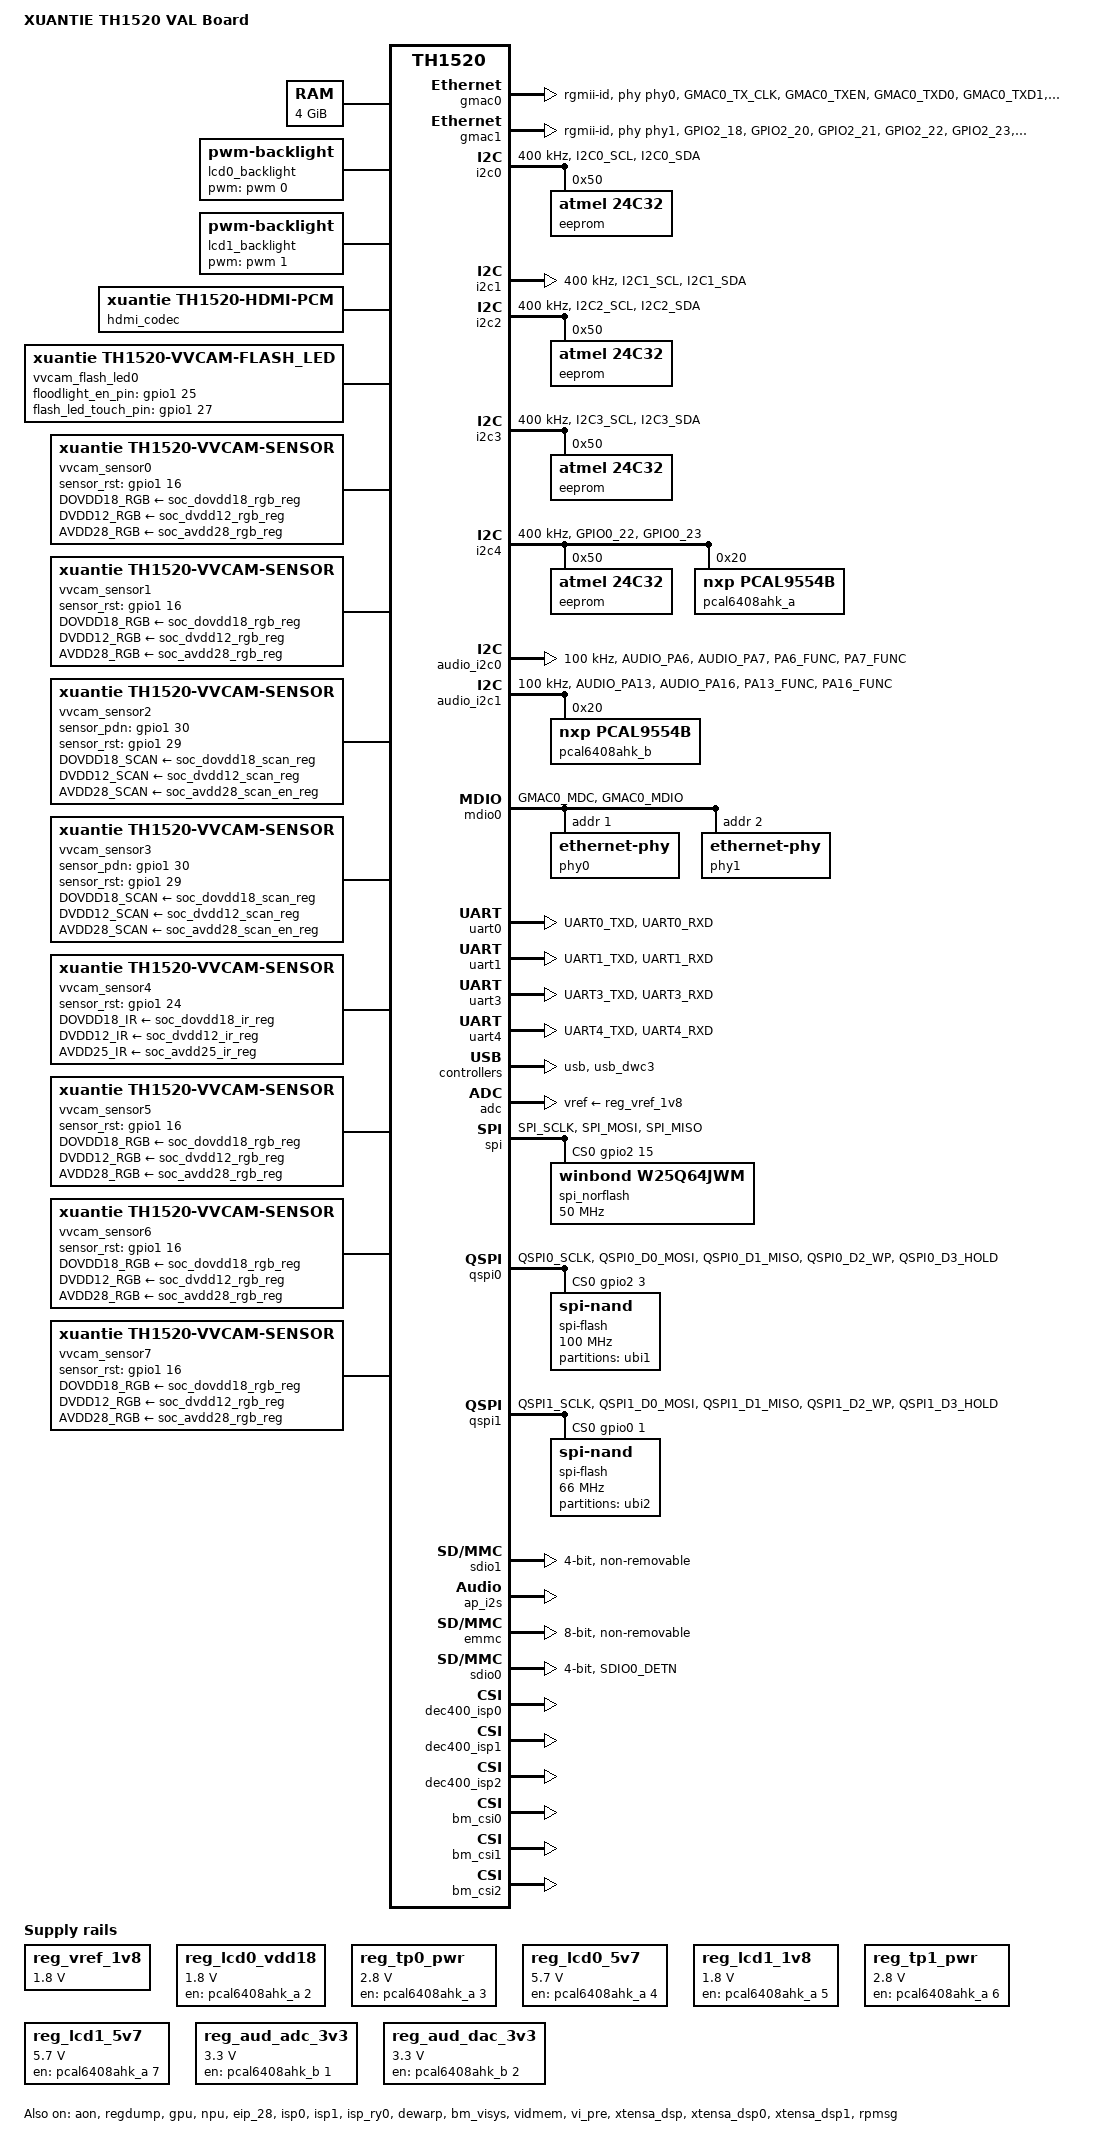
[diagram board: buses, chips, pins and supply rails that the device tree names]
/* SPDX-License-Identifier: GPL-2.0 */
/*
 * Copyright (C) 2021-2024 Alibaba Group Holding Limited.
 */

/dts-v1/;

#include "th1520.dtsi"
#include <dt-bindings/gpio/gpio.h>
#include "th1520-a-val-audio.dtsi"

/ {
	model = "XUANTIE TH1520 VAL Board";
	compatible = "xuantie,th1520-val", "xuantie,th1520", "thead,th1520";

	memory@0 {
		device_type = "memory";
		reg = <0x0 0x200000 0x0 0xffe00000>;
	};

	aliases {
		flash_led0 = &vvcam_flash_led0;
		vivcam0 = &vvcam_sensor0;
		vivcam1 = &vvcam_sensor1;
		vivcam2 = &vvcam_sensor2;
		vivcam3 = &vvcam_sensor3;
		vivcam4 = &vvcam_sensor4;
		vivcam5 = &vvcam_sensor5;
		vivcam6 = &vvcam_sensor6;
		vivcam7 = &vvcam_sensor7;
		viv_video0 =  &video0;
		viv_video1 =  &video1;
		viv_video2 =  &video2;
		viv_video3 =  &video3;
		viv_video4 =  &video4;
		viv_video5 =  &video5;
		viv_video6 =  &video6;
		viv_video7 =  &video7;
		viv_video8 =  &video8;
		viv_video9 =  &video9;
		viv_video10 =  &video10;
		viv_video11 =  &video11;
		viv_video12 =  &video12;
		viv_video15 =  &video15;

	};

	chosen {
		stdout-path = "serial0:115200n8";
	};

	lcd0_backlight: pwm-backlight@0 {
		compatible = "pwm-backlight";
		pwms = <&pwm 0 5000000 0>;
		pinctrl-names = "default";
		pinctrl-0 = <&pwm0_pins>;
		brightness-levels = <0 4 8 16 32 64 128 255>;
		default-brightness-level = <7>;
	};

	lcd1_backlight: pwm-backlight@1 {
		compatible = "pwm-backlight";
		pwms = <&pwm 1 5000000 0>;
		pinctrl-names = "default";
		pinctrl-0 = <&pwm1_pins>;
		brightness-levels = <0 4 8 16 32 64 128 255>;
		default-brightness-level = <7>;
	};

	th1520_iopmp: iopmp {
		compatible = "xuantie,th1520-iopmp";

		/* config#1: multiple valid regions */
		iopmp_emmc: IOPMP_EMMC {
			attr = <0xFFFFFFFF>;
			is_default_region;
		};

		/* config#2: iopmp bypass */
		iopmp_sdio0: IOPMP_SDIO0 {
			bypass_en;
		};

		/* config#3: iopmp default region set */
		iopmp_sdio1: IOPMP_SDIO1 {
			attr = <0xFFFFFFFF>;
			is_default_region;
		};

		iopmp_usb0: IOPMP_USB0 {
			attr = <0xFFFFFFFF>;
			is_default_region;
		};

		iopmp_ao: IOPMP_AO {
			is_default_region;
		};

		iopmp_aud: IOPMP_AUD {
			is_default_region;
		};

		iopmp_chip_dbg: IOPMP_CHIP_DBG {
			is_default_region;
		};

		iopmp_eip120i: IOPMP_EIP120I {
			is_default_region;
		};

		iopmp_eip120ii: IOPMP_EIP120II {
			is_default_region;
		};

		iopmp_eip120iii: IOPMP_EIP120III {
			is_default_region;
		};

		iopmp_isp0: IOPMP_ISP0 {
			is_default_region;
		};

		iopmp_isp1: IOPMP_ISP1 {
			is_default_region;
		};

		iopmp_dw200: IOPMP_DW200 {
			is_default_region;
		};

		iopmp_vipre: IOPMP_VIPRE {
			is_default_region;
		};

		iopmp_venc: IOPMP_VENC {
			is_default_region;
		};

		iopmp_vdec: IOPMP_VDEC {
			is_default_region;
		};

		iopmp_g2d: IOPMP_G2D {
			is_default_region;
		};

		iopmp_fce: IOPMP_FCE {
			is_default_region;
		};

		iopmp_npu: IOPMP_NPU {
			is_default_region;
		};

		iopmp0_dpu: IOPMP0_DPU {
			bypass_en;
		};

		iopmp1_dpu: IOPMP1_DPU {
			bypass_en;
		};

		iopmp_gpu: IOPMP_GPU {
			is_default_region;
		};

		iopmp_gmac1: IOPMP_GMAC1 {
			is_default_region;
		};

		iopmp_gmac2: IOPMP_GMAC2 {
			is_default_region;
		};

		iopmp_dmac: IOPMP_DMAC {
			is_default_region;
		};

		iopmp_tee_dmac: IOPMP_TEE_DMAC {
			is_default_region;
		};

		iopmp_dsp0: IOPMP_DSP0 {
			is_default_region;
		};

		iopmp_dsp1: IOPMP_DSP1 {
			is_default_region;
		};

		iopmp_audio0: IOPMP_AUDIO0 {
			is_default_region;
		};

		iopmp_audio1: IOPMP_AUDIO1 {
			is_default_region;
		};
	};

	reg_vref_1v8: regulator-adc-verf {
		compatible = "regulator-fixed";
		regulator-name = "vref-1v8";
		regulator-min-microvolt = <1800000>;
		regulator-max-microvolt = <1800000>;
		status = "okay";
	};

	reg_lcd0_vdd18: regulator-lcd0-vdd18 {
		compatible = "regulator-fixed";
		regulator-name = "lcd0_en";
		regulator-min-microvolt = <1800000>;
		regulator-max-microvolt = <1800000>;
		gpio = <&pcal6408ahk_a 2 GPIO_ACTIVE_HIGH>;
		enable-active-high;
	};

	reg_tp0_pwr: regulator-tp0-pwr {
		compatible = "regulator-fixed";
		regulator-name = "tp0_pwr";
		regulator-min-microvolt = <2800000>;
		regulator-max-microvolt = <2800000>;
		gpio = <&pcal6408ahk_a 3 GPIO_ACTIVE_HIGH>;
		enable-active-high;
		regulator-always-on;
	};

	reg_lcd0_5v7: regulator-lcd0-vspn57 {
		compatible = "regulator-fixed";
		regulator-name = "lcd0_bias_en";
		regulator-min-microvolt = <5700000>;
		regulator-max-microvolt = <5700000>;
		gpio = <&pcal6408ahk_a 4 GPIO_ACTIVE_HIGH>;
		enable-active-high;
	};

	reg_lcd1_1v8: regulator-lcd1-vdd18 {
		compatible = "regulator-fixed";
		regulator-name = "lcd1_en";
		regulator-min-microvolt = <1800000>;
		regulator-max-microvolt = <1800000>;
		gpio = <&pcal6408ahk_a 5 GPIO_ACTIVE_HIGH>;
		enable-active-high;
	};

	reg_tp1_pwr: regulator-tp1-pwr {
		compatible = "regulator-fixed";
		regulator-name = "tp1_pwr";
		regulator-min-microvolt = <2800000>;
		regulator-max-microvolt = <2800000>;
		gpio = <&pcal6408ahk_a 6 GPIO_ACTIVE_HIGH>;
		enable-active-high;
		regulator-always-on;
	};

	reg_lcd1_5v7: regulator-lcd1-vspn57 {
		compatible = "regulator-fixed";
		regulator-name = "lcd1_bias_en";
		regulator-min-microvolt = <5700000>;
		regulator-max-microvolt = <5700000>;
		gpio = <&pcal6408ahk_a 7 GPIO_ACTIVE_HIGH>;
		enable-active-high;
	};

	reg_aud_adc_3v3: regulator-aud-adc-3v3 {
		compatible = "regulator-fixed";
		regulator-name = "aud_adc_3v3_en";
		regulator-min-microvolt = <3300000>;
		regulator-max-microvolt = <3300000>;
		gpio = <&pcal6408ahk_b 1 GPIO_ACTIVE_HIGH>;
		enable-active-high;
	};

	reg_aud_dac_3v3: regulator-aud-dac-3v3 {
		compatible = "regulator-fixed";
		regulator-name = "aud_dac_3v3_en";
		regulator-min-microvolt = <3300000>;
		regulator-max-microvolt = <3300000>;
		gpio = <&pcal6408ahk_b 2 GPIO_ACTIVE_HIGH>;
		enable-active-high;
	};

	mbox_910t_client2: mbox_910t_client2 {
		compatible = "xuantie,th1520-mbox-client";
		mbox-names = "906";
		mboxes = <&mbox_910t 2 0>;
		audio-mbox-regmap = <&audio_mbox>;
		status = "okay";
	};

	th1520_rpmsg: th1520_rpmsg {
		compatible = "th1520,rpmsg-bus", "simple-bus";
		memory-region = <&rpmsgmem>;
		#address-cells = <2>;
		#size-cells = <2>;
		ranges;
		rpmsg: rpmsg{
			vdev-nums = <1>;
            reg = <0x0 0x1E000000 0 0x10000>;
			compatible = "th1520,th1520-rpmsg";
			log-memory-region = <&audio_log_mem>;
			audio-text-memory-region = <&audio_text_mem>;
			status = "okay";
		};
	};

	hdmi_codec: hdmi_codec@1 {
		#sound-dai-cells = <0>;
		compatible = "xuantie,th1520-hdmi-pcm";
		status = "okay";
		sound-name-prefix = "DUMMY";
	};

	wcn_wifi: wireless-wlan {
		compatible = "wlan-platdata";
		clock-names = "clk_wifi";
		ref-clock-frequency = <24000000>;
		keep_wifi_power_on;
		pinctrl-names = "default";
		pinctrl-0 = <&pinctrl_wifi_wake>;
		wifi_chip_type = "rtl8723ds";
		// WIFI,poweren-gpios = <&ioexp2 4 0>;	to be FIXED !!!
		support_power_ctrl;
		status = "disabled";
	};

	wcn_bt: wireless-bluetooth {
		compatible = "bluetooth-platdata";
		pinctrl-names = "default";
		pinctrl-0 = <&pinctrl_bt_wake>;
		// BT,power-gpios    = <&ioexp2 5 0>;	to be FIXED !!!
		status = "disabled";
	};

	thermal-zones {
		cpu-thermal {
			polling-delay = <1000>;
			polling-delay-passive = <1000>;
			thermal-sensors = <&pvt 0>;

			trips {
				trip_active0: active-0 {
					temperature = <39000>;
					hysteresis = <5000>;
					type = "active";
				};

				trip_active1: active-1 {
					temperature = <50000>;
					hysteresis = <5000>;
					type = "active";
				};

				trip_active2: active-2 {
					temperature = <60000>;
					hysteresis = <5000>;
					type = "active";
				};
			};
		};
	};

	soc {
		compatible = "simple-bus";
		interrupt-parent = <&plic>;
		#address-cells = <2>;
		#size-cells = <2>;
		dma-noncoherent;
		ranges;


		vvcam_flash_led0: vvcam_flash_led@0{
			flash_led_name = "aw36413_aw36515";
			compatible = "xuantie,th1520-vvcam-flash_led";
			floodlight_i2c_bus = /bits/ 8 <2>;
			floodlight_en_pin = <&gpio1 25 GPIO_ACTIVE_HIGH>;
			//projection_i2c_bus = /bits/ 8 <2>;
			flash_led_touch_pin = <&gpio1 27 GPIO_ACTIVE_HIGH>; //flash led touch pin
			status = "okay";
		};

		vvcam_sensor0: vvcam_sensor@0{
			sensor_name = "SC2310";
			compatible = "xuantie,th1520-vvcam-sensor";
			sensor_regulators = "DOVDD18_RGB", "DVDD12_RGB", "AVDD28_RGB";
			sensor_regulator_voltage_uV = <1800000 1200000 2800000>;
			sensor_regulator_timing_us = <70 50 20>;
			sensor_rst = <&gpio1 16 GPIO_ACTIVE_HIGH>;
			sensor_pdn_delay_us = <4000>; //powerdown pin / shutdown pin actived till I2C ready
			DOVDD18_RGB-supply = <&soc_dovdd18_rgb_reg>;
			DVDD12_RGB-supply = <&soc_dvdd12_rgb_reg>;
			AVDD28_RGB-supply = <&soc_avdd28_rgb_reg>;
			i2c_reg_width = /bits/ 8 <2>;
			i2c_data_width = /bits/ 8 <1>;
			i2c_addr = /bits/ 8 <0x30>;
			i2c_bus = /bits/ 8 <3>;
			status = "okay";
		};

		vvcam_sensor1: vvcam_sensor@1 {
			sensor_name = "OV5693";
			compatible = "xuantie,th1520-vvcam-sensor";
			sensor_regulators = "DOVDD18_RGB", "DVDD12_RGB", "AVDD28_RGB";
			sensor_regulator_voltage_uV = <1800000 1200000 2800000>;
			sensor_regulator_timing_us = <70 50 20>;
			sensor_rst = <&gpio1 16 GPIO_ACTIVE_HIGH>;
			sensor_pdn_delay_us = <4000>; //powerdown pin / shutdown pin actived till I2C ready
			DOVDD18_RGB-supply = <&soc_dovdd18_rgb_reg>;
			DVDD12_RGB-supply = <&soc_dvdd12_rgb_reg>;
			AVDD28_RGB-supply = <&soc_avdd28_rgb_reg>;
			i2c_reg_width = /bits/ 8 <2>;
			i2c_data_width = /bits/ 8 <1>;
			i2c_addr = /bits/ 8 <0x36>;
			i2c_bus = /bits/ 8 <3>;
			status = "okay";
		};

		vvcam_sensor2: vvcam_sensor@2 {
			sensor_name = "GC5035";
			compatible = "xuantie,th1520-vvcam-sensor";
			sensor_regulators = "DOVDD18_SCAN", "DVDD12_SCAN", "AVDD28_SCAN";
			sensor_regulator_timing_us = <100 50 0>;
			sensor_pdn = <&gpio1 30 GPIO_ACTIVE_HIGH>; //powerdown pin / shutdown pin
			sensor_rst = <&gpio1 29 GPIO_ACTIVE_HIGH>;
			sensor_pdn_delay_us = <60>; //powerdown pin / shutdown pin actived till I2C ready
			DOVDD18_SCAN-supply = <&soc_dovdd18_scan_reg>;
			DVDD12_SCAN-supply = <&soc_dvdd12_scan_reg>;
			AVDD28_SCAN-supply = <&soc_avdd28_scan_en_reg>;
			i2c_addr = /bits/ 8 <0x37>;
			i2c_bus = /bits/ 8 <4>;
			i2c_reg_width = /bits/ 8 <1>;
			i2c_data_width = /bits/ 8 <1>;
			status = "okay";
		};

		vvcam_sensor3: vvcam_sensor@3 {
			sensor_name = "SC2310";
			compatible = "xuantie,th1520-vvcam-sensor";
			sensor_regulators = "DOVDD18_SCAN", "DVDD12_SCAN", "AVDD28_SCAN";
			sensor_regulator_timing_us = <70 50 20>;
			sensor_pdn = <&gpio1 30 GPIO_ACTIVE_HIGH>; //powerdown pin / shutdown pin
			sensor_rst = <&gpio1 29 GPIO_ACTIVE_HIGH>;
			sensor_pdn_delay_us = <4000>; //powerdown pin / shutdown pin actived till I2C ready
			DOVDD18_SCAN-supply = <&soc_dovdd18_scan_reg>;
			DVDD12_SCAN-supply = <&soc_dvdd12_scan_reg>;
			AVDD28_SCAN-supply = <&soc_avdd28_scan_en_reg>;
			i2c_bus = /bits/ 8 <4>;
			i2c_reg_width = /bits/ 8 <2>;
			i2c_data_width = /bits/ 8 <1>;
			i2c_addr = /bits/ 8 <0x30>;
			status = "okay";
		};

		vvcam_sensor4: vvcam_sensor@4 {
			sensor_name = "SC132GS";
			compatible = "xuantie,th1520-vvcam-sensor";
			sensor_regulators = "DOVDD18_IR", "DVDD12_IR", "AVDD25_IR";
			sensor_regulator_timing_us = <70 1000 2000>;
			i2c_addr = /bits/ 8 <0x31>;
			sensor_rst = <&gpio1 24 GPIO_ACTIVE_HIGH>;
			sensor_pdn_delay_us = <2000>; //powerdown pin / shutdown pin actived till I2C ready
			DOVDD18_IR-supply = <&soc_dovdd18_ir_reg>;
			DVDD12_IR-supply = <&soc_dvdd12_ir_reg>;
			AVDD25_IR-supply = <&soc_avdd25_ir_reg>;
			i2c_reg_width = /bits/ 8 <2>;
			i2c_data_width = /bits/ 8 <1>;
			i2c_bus = /bits/ 8 <2>;
			status = "okay";
		};

		vvcam_sensor5: vvcam_sensor@5 {
			sensor_name = "OV12870";
			compatible = "xuantie,th1520-vvcam-sensor";
			sensor_regulators = "DOVDD18_RGB", "DVDD12_RGB", "AVDD28_RGB";
			sensor_regulator_voltage_uV = <1800000 1200000 2800000>;
			sensor_regulator_timing_us = <100 50 0>;
			sensor_rst = <&gpio1 16 GPIO_ACTIVE_HIGH>;
			sensor_pdn_delay_us = <60>; //powerdown pin / shutdown pin actived till I2C ready
			DOVDD18_RGB-supply = <&soc_dovdd18_rgb_reg>;
			DVDD12_RGB-supply = <&soc_dvdd12_rgb_reg>;
			AVDD28_RGB-supply = <&soc_avdd28_rgb_reg>;
			i2c_addr = /bits/ 8 <0x10>;
			i2c_reg_width = /bits/ 8 <2>;
			i2c_data_width = /bits/ 8 <1>;
			i2c_bus = /bits/ 8 <3>;
			status = "okay";
		};

		vvcam_sensor6: vvcam_sensor@6 {
			sensor_name = "GC02M1B";
			compatible = "xuantie,th1520-vvcam-sensor";
			sensor_regulators = "DOVDD18_RGB", "DVDD12_RGB", "AVDD28_RGB";
			sensor_regulator_voltage_uV = <1800000 1675000 2800000>;
			sensor_regulator_timing_us = <70 50 20>;
			sensor_rst = <&gpio1 16 GPIO_ACTIVE_HIGH>;
			sensor_pdn_delay_us = <1000>; //powerdown pin / shutdown pin actived till I2C ready
			DOVDD18_RGB-supply = <&soc_dovdd18_rgb_reg>;
			DVDD12_RGB-supply = <&soc_dvdd12_rgb_reg>;
			AVDD28_RGB-supply = <&soc_avdd28_rgb_reg>;
			i2c_reg_width = /bits/ 8 <1>;
			i2c_data_width = /bits/ 8 <1>;
			i2c_addr = /bits/ 8 <0x37>;
			i2c_bus = /bits/ 8 <3>;
			status = "okay";
		};

		vvcam_sensor7: vvcam_sensor@7 {
			sensor_name = "IMX334";
			compatible = "xuantie,th1520-vvcam-sensor";
			sensor_regulators = "DOVDD18_RGB", "DVDD12_RGB", "AVDD28_RGB";
			sensor_regulator_timing_us = <70 50 20>;
			sensor_rst = <&gpio1 16 GPIO_ACTIVE_HIGH>;
			sensor_pdn_delay_us = <1000>; //powerdown pin / shutdown pin actived till I2C ready
			DOVDD18_RGB-supply = <&soc_dovdd18_rgb_reg>;
			DVDD12_RGB-supply = <&soc_dvdd12_rgb_reg>;
			AVDD28_RGB-supply = <&soc_avdd28_rgb_reg>;
			i2c_reg_width = /bits/ 8 <2>;
			i2c_data_width = /bits/ 8 <1>;
			i2c_addr = /bits/ 8 <0x1a>;
			i2c_bus = /bits/ 8 <3>;
			status = "okay";
		};

		video0: cam_dev@000 {
			compatible = "xuantie,th1520-video";
			status = "okay";
			vi_mem_pool_region = <2>;	// vi_mem: framebuffer, region[2]
			channel0 {
				sensor0 {
					subdev_name = "vivcam";
					idx = <2>; //<2>=vivcam2 : gc5035
					csi_idx = <1>; //<1>=CSI2X2_B
					mode_idx = <3>;
					path_type = "SENSOR_1296x972_RAW10_LINER"; //SENSOR_VGA_RAW10_LINER//
				};
				sensor1 {
					subdev_name = "vivcam";
					idx = <3>; //<3>=vivcam3 : sc2310
					csi_idx = <1>; //<1>=CSI2X2_B
					mode_idx = <1>;
					path_type = "SENSOR_1920X1088_26FPS_RAW12_LINER";
				};
				dma {
					subdev_name = "vipre";
					idx = <0>;
					path_type = "VIPRE_CSI1_ISP0";
				};
				isp {
					subdev_name = "isp";
					idx = <0>;
					path_type = "ISP_MI_PATH_MP";
					output {
						max_width = <1920>;
						max_height = <1088>;
						bit_per_pixel = <12>;
						frame_count = <3>;
					};
				};
			};
			channel1 {
				sensor0 {
					subdev_name = "vivcam";
					idx = <2>; //<2>=vivcam2 : gc5035
					csi_idx = <1>; //<1>=CSI2X2_B
					mode_idx = <3>;
					path_type = "SENSOR_1296x972_RAW10_LINER"; //SENSOR_VGA_RAW10_LINER//
				};
				sensor1 {
					subdev_name = "vivcam";
					idx = <3>; //<3>=vivcam3 : sc2310
					csi_idx = <1>; //<1>=CSI2X2_B
					mode_idx = <1>;
					path_type = "SENSOR_1920X1088_26FPS_RAW12_LINER";
				};
				dma {
					subdev_name = "vipre";
					idx = <0>;
					path_type = "VIPRE_CSI1_ISP0";
				};
				isp {
					subdev_name = "isp";
					idx = <0>;
					path_type = "ISP_MI_PATH_SP";
					output {
						max_width = <1920>;
						max_height = <1088>;
						bit_per_pixel = <12>;
						frame_count = <3>;
					};
				};
			};
			channel2 {
				sensor0 {
					subdev_name = "vivcam";
					idx = <2>; //<2>=vivcam2 : gc5035
					csi_idx = <1>; //<1>=CSI2X2_B
					mode_idx = <3>;
					path_type = "SENSOR_1296x972_RAW10_LINER"; //SENSOR_VGA_RAW10_LINER//
				};
				sensor1 {
					subdev_name = "vivcam";
					idx = <3>; //<3>=vivcam3 : sc2310
					csi_idx = <1>; //<1>=CSI2X2_B
					mode_idx = <1>;
					path_type = "SENSOR_1920X1088_26FPS_RAW12_LINER";
				};
				dma {
					subdev_name = "vipre";
					idx = <0>;
					path_type = "VIPRE_CSI1_ISP0";
				};
				isp {
					subdev_name = "isp";
					idx = <0>;
					path_type = "ISP_MI_PATH_SP2_BP";
					output {
						max_width = <1920>;
						max_height = <1088>;
						bit_per_pixel = <12>;
						frame_count = <3>;
					};
				};
			};
		};


		video1: cam_dev@100{
			compatible = "xuantie,th1520-video";
			status = "okay";
			vi_mem_pool_region = <2>;	// vi_mem: framebuffer, region[2]
			channel0 {
				sensor0 {
					subdev_name = "vivcam";
					idx = <2>; //<2>=vivcam2 : gc5035
					csi_idx = <1>; //<1>=CSI2X2_B
					mode_idx = <3>;
					path_type = "SENSOR_1296x972_RAW10_LINER";
				};
				sensor1 {
					subdev_name = "vivcam";
					idx = <3>; //<3>=vivcam3 : sc2310
					csi_idx = <1>; //<1>=CSI2X2_B
					mode_idx = <1>;
					path_type = "SENSOR_1920X1088_26FPS_RAW12_LINER";
				};
				dma {
					subdev_name = "vipre";
					idx = <0>;
					path_type = "VIPRE_CSI1_ISP0";
				};
				isp {
					subdev_name = "isp";
					idx = <0>;
					path_type = "ISP_MI_PATH_MP";
					output {
						max_width = <1920>;
						max_height = <1088>;
						bit_per_pixel = <12>;
						frame_count = <3>;
					};
				};
				dw {
					subdev_name = "dw";
					idx = <0>;
					path_type = "DW_DWE_VSE0";
					dw_dst_depth = <2>;
				};
			};
			channel1 {
				sensor0 {
					subdev_name = "vivcam";
					idx = <2>; //<2>=vivcam2 : gc5035
					csi_idx = <1>; //<1>=CSI2X2_B
					mode_idx = <3>;
					path_type = "SENSOR_1296x972_RAW10_LINER";
				};
				sensor1 {
					subdev_name = "vivcam";
					idx = <3>; //<3>=vivcam3 : sc2310
					csi_idx = <1>; //<1>=CSI2X2_B
					mode_idx = <1>;
					path_type = "SENSOR_1920X1088_26FPS_RAW12_LINER";
				};
				dma {
					subdev_name = "vipre";
					idx = <0>;
					path_type = "VIPRE_CSI1_ISP0";
				};
				isp {
					subdev_name = "isp";
					idx = <0>;
					path_type = "ISP_MI_PATH_MP";
					output {
						max_width = <1920>;
						max_height = <1088>;
						bit_per_pixel = <12>;
						frame_count = <3>;
					};
				};
				dw {
					subdev_name = "dw";
					idx = <0>;
					path_type = "DW_DWE_VSE1";
					dw_dst_depth = <2>;
				};
			};
			channel2 {
				sensor0 {
					subdev_name = "vivcam";
					idx = <2>; //<2>=vivcam2 : gc5035
					csi_idx = <1>; //<1>=CSI2X2_B
					mode_idx = <3>;
					path_type = "SENSOR_1296x972_RAW10_LINER";
				};
				sensor1 {
					subdev_name = "vivcam";
					idx = <3>; //<3>=vivcam3 : sc2310
					csi_idx = <1>; //<1>=CSI2X2_B
					mode_idx = <1>;
					path_type = "SENSOR_1920X1088_26FPS_RAW12_LINER";
				};
				dma {
					subdev_name = "vipre";
					idx = <0>;
					path_type = "VIPRE_CSI1_ISP0";
				};
				isp {
					subdev_name = "isp";
					idx = <0>;
					path_type = "ISP_MI_PATH_MP";
					output {
						max_width = <1920>;
						max_height = <1088>;
						bit_per_pixel = <12>;
						frame_count = <3>;
					};
				};
				dw {
					subdev_name = "dw";
					idx = <0>;
					path_type = "DW_DWE_VSE2";
					dw_dst_depth = <2>;
				};
			};
		};

		video2: cam_dev@200{
			compatible = "xuantie,th1520-video";
			status = "okay";
			vi_mem_pool_region = <0>;	// vi_mem: framebuffer, region[0]
			channel0 {
				sensor0 {
					subdev_name = "vivcam";
					idx = <0>; //sc2310
					csi_idx = <0>; //<0>=CSI2
					mode_idx = <1>;
					path_type = "SENSOR_1920X1088_26FPS_RAW12_LINER";
				};
				sensor1 {
					subdev_name = "vivcam";
					idx = <6>; //gc02m1b
					csi_idx = <0>; //<0>=CSI2
					mode_idx = <0>;
					path_type = "SENSOR_1600x1200_RAW10_LINER";
				};
				sensor2 {
					subdev_name = "vivcam";
					idx = <7>; //imx334
					csi_idx = <0>; //<0>=CSI2
					mode_idx = <0>;
					path_type = "SENSOR_3840x2180_RAW12_LINER";
				};
				dma {
					subdev_name = "vipre";
					idx = <0>;
					path_type = "VIPRE_CSI0_ISP1";
				};
				isp {
					subdev_name = "isp";
					idx = <1>;
					path_type = "ISP_MI_PATH_MP";
					output {
						max_width = <3840>;
						max_height = <2180>;
						bit_per_pixel = <16>;
						frame_count = <3>;
					};
				};
			};
			channel1 {
				sensor0 {
					subdev_name = "vivcam";
					idx = <0>; //sc2310
					csi_idx = <0>; //<0>=CSI2
					mode_idx = <1>;
					path_type = "SENSOR_1920X1088_26FPS_RAW12_LINER";
				};
				sensor1 {
					subdev_name = "vivcam";
					idx = <6>; //gc02m1b
					csi_idx = <0>; //<0>=CSI2
					mode_idx = <0>;
					path_type = "SENSOR_1600x1200_RAW10_LINER";
				};
				dma {
					subdev_name = "vipre";
					idx = <0>;
					path_type = "VIPRE_CSI0_ISP1";
				};
				isp {
					subdev_name = "isp";
					idx = <1>;
					path_type = "ISP_MI_PATH_SP";
					output {
						max_width = <1920>;
						max_height = <1088>;
						bit_per_pixel = <16>;
						frame_count = <3>;
					};
				};
			};
			channel2 {
				sensor0 {
					subdev_name = "vivcam";
					idx = <0>; //sc2310
					csi_idx = <0>; //<0>=CSI2
					mode_idx = <1>;
					path_type = "SENSOR_1920X1088_26FPS_RAW12_LINER";
				};
				sensor1 {
					subdev_name = "vivcam";
					idx = <6>; //gc02m1b
					csi_idx = <0>; //<0>=CSI2
					mode_idx = <0>;
					path_type = "SENSOR_1600x1200_RAW10_LINER";
				};
				dma {
					subdev_name = "vipre";
					idx = <0>;
					path_type = "VIPRE_CSI0_ISP1";
				};
				isp {
					subdev_name = "isp";
					idx = <1>;
					path_type = "ISP_MI_PATH_SP2_BP";
					output {
						max_width = <1920>;
						max_height = <1088>;
						bit_per_pixel = <16>;
						frame_count = <3>;
					};
				};
			};
		};

		video3: cam_dev@300{
			compatible = "xuantie,th1520-video";
			status = "okay";
			vi_mem_pool_region = <0>;	// vi_mem: framebuffer, region[0]
			channel0 {
				sensor0 {
					subdev_name = "vivcam";
					idx = <0>; //sc2310
					csi_idx = <0>; //<0>=CSI2
					mode_idx = <1>;
					path_type = "SENSOR_1920X1088_26FPS_RAW12_LINER";
				};
				sensor1 {
					subdev_name = "vivcam";
					idx = <6>; //gc02m1b
					csi_idx = <0>; //<0>=CSI2
					mode_idx = <0>;
					path_type = "SENSOR_1600x1200_RAW10_LINER";
				};
				dma {
					subdev_name = "vipre";
					idx = <0>;
					path_type = "VIPRE_CSI0_ISP1";
				};
				isp {
					subdev_name = "isp";
					idx = <1>;
					path_type = "ISP_MI_PATH_MP";
					output {
						max_width = <1920>;
						max_height = <1088>;
						bit_per_pixel = <12>;
						frame_count = <3>;
					};
				};
				dw {
					subdev_name = "dw";
					idx = <0>;
					path_type = "DW_DWE_VSE0";
					dw_dst_depth = <2>;
				};
			};
			channel1 {
				sensor0 {
					subdev_name = "vivcam";
					idx = <0>; //sc2310
					csi_idx = <0>; //<0>=CSI2
					mode_idx = <1>;
					path_type = "SENSOR_1920X1088_26FPS_RAW12_LINER";
				};
				sensor1 {
					subdev_name = "vivcam";
					idx = <6>; //gc02m1b
					csi_idx = <0>; //<0>=CSI2
					mode_idx = <0>;
					path_type = "SENSOR_1600x1200_RAW10_LINER";
				};
				dma {
					subdev_name = "vipre";
					idx = <0>;
					path_type = "VIPRE_CSI0_ISP1";
				};
				isp {
					subdev_name = "isp";
					idx = <1>;
					path_type = "ISP_MI_PATH_MP";
					output {
						max_width = <1920>;
						max_height = <1088>;
						bit_per_pixel = <12>;
						frame_count = <3>;
					};
				};
				dw {
					subdev_name = "dw";
					idx = <0>;
					path_type = "DW_DWE_VSE1";
					dw_dst_depth = <2>;
				};
			};
			channel2 {
				sensor0 {
					subdev_name = "vivcam";
					idx = <0>; //sc2310
					csi_idx = <0>; //<0>=CSI2
					mode_idx = <1>;
					path_type = "SENSOR_1920X1088_26FPS_RAW12_LINER";
				};
				sensor1 {
					subdev_name = "vivcam";
					idx = <6>; //gc02m1b
					csi_idx = <0>; //<0>=CSI2
					mode_idx = <0>;
					path_type = "SENSOR_1600x1200_RAW10_LINER";
				};
				dma {
					subdev_name = "vipre";
					idx = <0>;
					path_type = "VIPRE_CSI0_ISP1";
				};
				isp {
					subdev_name = "isp";
					idx = <1>;
					path_type = "ISP_MI_PATH_MP";
					output {
						max_width = <1920>;
						max_height = <1088>;
						bit_per_pixel = <12>;
						frame_count = <3>;
					};
				};
				dw {
					subdev_name = "dw";
					idx = <0>;
					path_type = "DW_DWE_VSE2";
					dw_dst_depth = <2>;
				};
			};
		};

		video4: cam_dev@400{
			compatible = "xuantie,th1520-video";
			status = "okay";
			vi_mem_pool_region = <0>;	// vi_mem: framebuffer, region[0]
			channel0 {
				sensor0 {
					subdev_name = "vivcam";
					idx = <0>; //sc2310
					csi_idx = <0>; //<0>=CSI2
					mode_idx = <1>;
					path_type = "SENSOR_1920X1088_26FPS_RAW12_LINER";
				};
				sensor1 {
					subdev_name = "vivcam";
					idx = <6>; //gc02m1b
					csi_idx = <0>; //<0>=CSI2
					mode_idx = <0>;
					path_type = "SENSOR_1600x1200_RAW10_LINER";
				};
				dma {
					subdev_name = "vipre";
					idx = <0>;
					path_type = "VIPRE_CSI0_ISP1";
				};
				isp {
					subdev_name = "isp";
					idx = <1>;
					path_type = "ISP_MI_PATH_PP";
					output {
						max_width = <1920>;
						max_height = <1088>;
						bit_per_pixel = <12>;
						frame_count = <3>;
					};
				};
				dsp {
					subdev_name = "dsp";
					idx = <0>;
					path_type = "DSP_PATH_ISP_RY";
					output {
						max_width = <1920>;
						max_height = <1088>;
						bit_per_pixel = <12>;
						frame_count = <3>;
					};
				};
				ry {
					subdev_name = "ry";
					idx = <0>;
					path_type = "ISP_RY_MI_PATH_MP";
					output {
						max_width = <1920>;
						max_height = <1088>;
						bit_per_pixel = <12>;
						frame_count = <3>;
					};
				};
			};
			channel1 {
				sensor0 {
					subdev_name = "vivcam";
					idx = <0>; //sc2310
					csi_idx = <0>; //<0>=CSI2
					mode_idx = <1>;
					path_type = "SENSOR_1920X1088_26FPS_RAW12_LINER";
				};
				sensor1 {
					subdev_name = "vivcam";
					idx = <6>; //gc02m1b
					csi_idx = <0>; //<0>=CSI2
					mode_idx = <0>;
					path_type = "SENSOR_1600x1200_RAW10_LINER";
				};
				dma {
					subdev_name = "vipre";
					idx = <0>;
					path_type = "VIPRE_CSI0_ISP1";
				};
				isp {
					subdev_name = "isp";
					idx = <1>;
					path_type = "ISP_MI_PATH_PP";
					output {
						max_width = <1920>;
						max_height = <1088>;
						bit_per_pixel = <12>;
						frame_count = <3>;
					};
				};
				dsp {
					subdev_name = "dsp";
					idx = <0>;
					path_type = "DSP_PATH_ISP_RY";
					output {
						max_width = <1920>;
						max_height = <1088>;
						bit_per_pixel = <12>;
						frame_count = <3>;
					};
				};
				ry {
					subdev_name = "ry";
					idx = <0>;
					path_type = "ISP_RY_MI_PATH_SP";
					output {
						max_width = <1920>;
						max_height = <1088>;
						bit_per_pixel = <12>;
						frame_count = <3>;
					};
				};
			};
			channel2 {
				sensor0 {
					subdev_name = "vivcam";
					idx = <0>; //sc2310
					csi_idx = <0>; //<0>=CSI2
					mode_idx = <1>;
					path_type = "SENSOR_1920X1088_26FPS_RAW12_LINER";
				};
				sensor1 {
					subdev_name = "vivcam";
					idx = <6>; //gc02m1b
					csi_idx = <0>; //<0>=CSI2
					mode_idx = <0>;
					path_type = "SENSOR_1600x1200_RAW10_LINER";
				};
				dma {
					subdev_name = "vipre";
					idx = <0>;
					path_type = "VIPRE_CSI0_ISP1";
				};
				isp {
					subdev_name = "isp";
					idx = <1>;
					path_type = "ISP_MI_PATH_PP";
					output {
						max_width = <1920>;
						max_height = <1088>;
						bit_per_pixel = <12>;
						frame_count = <3>;
					};
				};
				dsp {
					subdev_name = "dsp";
					idx = <0>;
					path_type = "DSP_PATH_ISP_RY";
					output {
						max_width = <1920>;
						max_height = <1088>;
						bit_per_pixel = <12>;
						frame_count = <3>;
					};
				};
				ry {
					subdev_name = "ry";
					idx = <0>;
					path_type = "ISP_RY_MI_PATH_SP2_BP";
					output {
						max_width = <1920>;
						max_height = <1088>;
						bit_per_pixel = <12>;
						frame_count = <3>;
					};
				};
			};
		};

		video5: cam_dev@500{
			compatible = "xuantie,th1520-video";
			status = "okay";
			vi_mem_pool_region = <0>;	// vi_mem: framebuffer, region[0]
			channel0 {
				sensor0 {
					subdev_name = "vivcam";
					idx = <0>; //sc2310
					csi_idx = <0>; //<0>=CSI2
					mode_idx = <1>;
					path_type = "SENSOR_1920X1088_26FPS_RAW12_LINER";
				};
				sensor1 {
					subdev_name = "vivcam";
					idx = <6>; //gc02m1b
					csi_idx = <0>; //<0>=CSI2
					mode_idx = <0>;
					path_type = "SENSOR_1600x1200_RAW10_LINER";
				};
				dma {
					subdev_name = "vipre";
					idx = <0>;
					path_type = "VIPRE_CSI0_ISP1";
				};
				isp {
					subdev_name = "isp";
					idx = <1>;
					path_type = "ISP_MI_PATH_PP";
					output {
						max_width = <1920>;
						max_height = <1088>;
						bit_per_pixel = <12>;
						frame_count = <3>;
					};
				};
				dsp {
					subdev_name = "dsp";
					idx = <0>;
					path_type = "DSP_PATH_ISP_RY";
					output {
						max_width = <1920>;
						max_height = <1088>;
						bit_per_pixel = <12>;
						frame_count = <3>;
					};
				};
				ry {
					subdev_name = "ry";
					idx = <0>;
					path_type = "ISP_RY_MI_PATH_MP";
					output {
						max_width = <1920>;
						max_height = <1088>;
						bit_per_pixel = <12>;
						frame_count = <3>;
					};
				};
				dw {
					subdev_name = "dw";
					idx = <0>;
					path_type = "DW_DWE_VSE0";
					dw_dst_depth = <2>;
				};
			};
			channel1 {
				sensor0 {
					subdev_name = "vivcam";
					idx = <0>; //sc2310
					csi_idx = <0>; //<0>=CSI2
					mode_idx = <1>;
					path_type = "SENSOR_1920X1088_26FPS_RAW12_LINER";
				};
				sensor1 {
					subdev_name = "vivcam";
					idx = <6>; //gc02m1b
					csi_idx = <0>; //<0>=CSI2
					mode_idx = <0>;
					path_type = "SENSOR_1600x1200_RAW10_LINER";
				};
				dma {
					subdev_name = "vipre";
					idx = <0>;
					path_type = "VIPRE_CSI0_ISP1";
				};
				isp {
					subdev_name = "isp";
					idx = <1>;
					path_type = "ISP_MI_PATH_PP";
					output {
						max_width = <1920>;
						max_height = <1088>;
						bit_per_pixel = <12>;
						frame_count = <3>;
					};
				};
				dsp {
					subdev_name = "dsp";
					idx = <0>;
					path_type = "DSP_PATH_ISP_RY";
					output {
						max_width = <1920>;
						max_height = <1088>;
						bit_per_pixel = <12>;
						frame_count = <3>;
					};
				};
				ry {
					subdev_name = "ry";
					idx = <0>;
					path_type = "ISP_RY_MI_PATH_MP";
					output {
						max_width = <1920>;
						max_height = <1088>;
						bit_per_pixel = <12>;
						frame_count = <3>;
					};
				};
				dw {
					subdev_name = "dw";
					idx = <0>;
					path_type = "DW_DWE_VSE1";
					dw_dst_depth = <2>;
				};
			};
			channel2 {
				sensor0 {
					subdev_name = "vivcam";
					idx = <0>; //sc2310
					csi_idx = <0>; //<0>=CSI2
					mode_idx = <1>;
					path_type = "SENSOR_1920X1088_26FPS_RAW12_LINER";
				};
				sensor1 {
					subdev_name = "vivcam";
					idx = <6>; //gc02m1b
					csi_idx = <0>; //<0>=CSI2
					mode_idx = <0>;
					path_type = "SENSOR_1600x1200_RAW10_LINER";
				};
				dma {
					subdev_name = "vipre";
					idx = <0>;
					path_type = "VIPRE_CSI0_ISP1";
				};
				isp {
					subdev_name = "isp";
					idx = <1>;
					path_type = "ISP_MI_PATH_PP";
					output {
						max_width = <1920>;
						max_height = <1088>;
						bit_per_pixel = <12>;
						frame_count = <3>;
					};
				};
				dsp {
					subdev_name = "dsp";
					idx = <0>;
					path_type = "DSP_PATH_ISP_RY";
					output {
						max_width = <1920>;
						max_height = <1088>;
						bit_per_pixel = <12>;
						frame_count = <3>;
					};
				};
				ry {
					subdev_name = "ry";
					idx = <0>;
					path_type = "ISP_RY_MI_PATH_MP";
					output {
						max_width = <1920>;
						max_height = <1088>;
						bit_per_pixel = <12>;
						frame_count = <3>;
					};
				};
				dw {
					subdev_name = "dw";
					idx = <0>;
					path_type = "DW_DWE_VSE2";
					dw_dst_depth = <2>;
				};
			};
		};

		video6: cam_dev@600{
			compatible = "xuantie,th1520-video";
			status = "okay";
			vi_mem_pool_region = <1>;	// vi_mem: framebuffer, region[1]
			channel0 {
				sensor0 {
					subdev_name = "vivcam";
					idx = <4>; //sc132gs
					csi_idx = <2>; //<2>=CSI2X2_A
					flash_led_idx = <0>;
					mode_idx = <0>;
					path_type = "SENSOR_1080X1280_30FPS_RAW10_LINER";
				};
				dma {
					subdev_name = "vipre";
					idx = <0>;
					path_type = "VIPRE_CSI2_DSP";
				};
				dsp{
					subdev_name = "dsp";
					idx = <1>;
					path_type = "DSP_PATH_VIPRE_ODD";
					output {
						max_width = <1080>;
						max_height = <1280>;
						bit_per_pixel = <16>;
						frame_count = <3>;
					};
				};
			};
			channel1 {
				sensor0 {
					subdev_name = "vivcam";
					idx = <4>; //sc132gs
					csi_idx = <2>; //<2>=CSI2X2_A
					flash_led_idx = <0>;
					mode_idx = <0>;
					path_type = "SENSOR_1080X1280_30FPS_RAW10_LINER";
				};
				dma {
					subdev_name = "vipre";
					idx = <0>;
					path_type = "VIPRE_CSI2_DSP";
				};
				dsp{
					subdev_name = "dsp";
					idx = <1>;
					path_type = "DSP_PATH_VIPRE_EVEN";
					output {
						max_width = <1080>;
						max_height = <1280>;
						bit_per_pixel = <16>;
						frame_count = <3>;
					};
				};
			};
		};

		video7: cam_dev@700{
			compatible = "xuantie,th1520-video";
			status = "okay";
			channel0 {
				sensor0 {
					subdev_name = "vivcam";
					idx = <2>; //<2>=vivcam2 : gc5035
					csi_idx = <1>; //<1>=CSI2X2_B
					mode_idx = <3>;
					path_type = "SENSOR_1296x972_RAW10_LINER"; //SENSOR_VGA_RAW10_LINER//
				};
				sensor1 {
					subdev_name = "vivcam";
					idx = <3>; //<3>=vivcam3 : sc2310
					csi_idx = <1>; //<1>=CSI2X2_B
					mode_idx = <1>;
					path_type = "SENSOR_1920X1088_26FPS_RAW12_LINER";
				};
				dma {
					subdev_name = "vipre";
					idx = <0>;
					path_type = "VIPRE_CSI1_ISP0";
				};
				isp {
					subdev_name = "isp";
					idx = <0>;
					path_type = "ISP_MI_PATH_PP";
					output {
						max_width = <1920>;
						max_height = <1088>;
						bit_per_pixel = <12>;
						frame_count = <3>;
					};
				};
				dsp {
					subdev_name = "dsp";
					idx = <1>;
					path_type = "DSP_PATH_ISP_RY";
					output {
						max_width = <1920>;
						max_height = <1088>;
						bit_per_pixel = <12>;
						frame_count = <3>;
					};
				};
				ry {
					subdev_name = "ry";
					idx = <0>;
					path_type = "ISP_RY_MI_PATH_MP";
					output {
						max_width = <1920>;
						max_height = <1088>;
						bit_per_pixel = <12>;
						frame_count = <3>;
					};
				};
				dw {
					subdev_name = "dw";
					idx = <0>;
					path_type = "DW_DWE_VSE0";
					dw_dst_depth = <2>;
				};
			};
			channel1 {
				sensor0 {
					subdev_name = "vivcam";
					idx = <2>; //<2>=vivcam2 : gc5035
					csi_idx = <1>; //<1>=CSI2X2_B
					mode_idx = <3>;
					path_type = "SENSOR_1296x972_RAW10_LINER"; //SENSOR_VGA_RAW10_LINER//
				};
				sensor1 {
					subdev_name = "vivcam";
					idx = <3>; //<3>=vivcam3 : sc2310
					csi_idx = <1>; //<1>=CSI2X2_B
					mode_idx = <1>;
					path_type = "SENSOR_1920X1088_26FPS_RAW12_LINER";
				};
				dma {
					subdev_name = "vipre";
					idx = <0>;
					path_type = "VIPRE_CSI1_ISP0";
				};
				isp {
					subdev_name = "isp";
					idx = <0>;
					path_type = "ISP_MI_PATH_PP";
					output {
						max_width = <1920>;
						max_height = <1088>;
						bit_per_pixel = <12>;
						frame_count = <3>;
					};
				};
				dsp {
					subdev_name = "dsp";
					idx = <1>;
					path_type = "DSP_PATH_ISP_RY";
					output {
						max_width = <1920>;
						max_height = <1088>;
						bit_per_pixel = <12>;
						frame_count = <3>;
					};
				};
				ry {
					subdev_name = "ry";
					idx = <0>;
					path_type = "ISP_RY_MI_PATH_MP";
					output {
						max_width = <1920>;
						max_height = <1088>;
						bit_per_pixel = <12>;
						frame_count = <3>;
					};
				};
				dw {
					subdev_name = "dw";
					idx = <0>;
					path_type = "DW_DWE_VSE1";
					dw_dst_depth = <2>;
				};
			};
			channel2 {
				sensor0 {
					subdev_name = "vivcam";
					idx = <2>; //<2>=vivcam2 : gc5035
					csi_idx = <1>; //<1>=CSI2X2_B
					mode_idx = <3>;
					path_type = "SENSOR_1296x972_RAW10_LINER"; //SENSOR_VGA_RAW10_LINER//
				};
				sensor1 {
					subdev_name = "vivcam";
					idx = <3>; //<3>=vivcam3 : sc2310
					csi_idx = <1>; //<1>=CSI2X2_B
					mode_idx = <1>;
					path_type = "SENSOR_1920X1088_26FPS_RAW12_LINER";
				};
				dma {
					subdev_name = "vipre";
					idx = <0>;
					path_type = "VIPRE_CSI1_ISP0";
				};
				isp {
					subdev_name = "isp";
					idx = <0>;
					path_type = "ISP_MI_PATH_PP";
					output {
						max_width = <1920>;
						max_height = <1088>;
						bit_per_pixel = <12>;
						frame_count = <3>;
					};
				};
				dsp {
					subdev_name = "dsp";
					idx = <1>;
					path_type = "DSP_PATH_ISP_RY";
					output {
						max_width = <1920>;
						max_height = <1088>;
						bit_per_pixel = <12>;
						frame_count = <3>;
					};
				};
				ry {
					subdev_name = "ry";
					idx = <0>;
					path_type = "ISP_RY_MI_PATH_MP";
					output {
						max_width = <1920>;
						max_height = <1088>;
						bit_per_pixel = <12>;
						frame_count = <3>;
					};
				};
				dw {
					subdev_name = "dw";
					idx = <0>;
					path_type = "DW_DWE_VSE2";
					dw_dst_depth = <2>;
				};
			};
		};


		video8: cam_dev@800{
			compatible = "xuantie,th1520-video";
			status = "okay";
			vi_mem_pool_region = <1>;	// vi_mem: framebuffer, region[1]
			channel0 {
				sensor0 {
					subdev_name = "vivcam";
					idx = <2>; //<2>=vivcam2 : gc5035
					csi_idx = <1>; //<1>=CSI2X2_B
					mode_idx = <3>;
					path_type = "SENSOR_1296x972_RAW10_LINER"; //SENSOR_VGA_RAW10_LINER//
				};
				sensor1 {
					subdev_name = "vivcam";
					idx = <3>; //<3>=vivcam3 : sc2310
					csi_idx = <1>; //<1>=CSI2X2_B
					mode_idx = <1>;
					path_type = "SENSOR_1920X1088_26FPS_RAW12_LINER";
				};
				dma {
					subdev_name = "vipre";
					idx = <0>;
					path_type = "VIPRE_CSI1_DSP";
				};
				dsp {
					subdev_name = "dsp";
					idx = <0>;
					path_type = "DSP_PATH_VIPRE_DDR";
					output {
						max_width = <1920>;
						max_height = <1088>;
						bit_per_pixel = <12>;
						frame_count = <3>;
					};
				};
			};
		};

		video9: cam_dev@900{
			compatible = "xuantie,th1520-video";
			status = "okay";
			channel0 {
				sensor0 {
					subdev_name = "vivcam";
					idx = <4>; //sc132gs
					csi_idx = <2>; //<2>=CSI2X2_A
					mode_idx = <0>;
					path_type = "SENSOR_1080X1280_30FPS_RAW10_LINER";
				};
				dma {
					subdev_name = "vipre";
					idx = <0>;
					path_type = "VIPRE_CSI2_DSP";
				};
				dsp{
					subdev_name = "dsp";
					idx = <1>;
					path_type = "DSP_PATH_VIPRE_DDR";
					output {
						max_width = <1080>;
						max_height = <1280>;
						bit_per_pixel = <16>;
						frame_count = <3>;
					};
				};
			};
		};


		video10: cam_dev@a00{
			compatible = "xuantie,th1520-video";
			status = "okay";
			channel0 {
				sensor0 {
					subdev_name = "vivcam";
					idx = <2>; //<2>=vivcam2 : gc5035
					csi_idx = <1>; //<1>=CSI2X2_B
					mode_idx = <1>;
					path_type = "SENSOR_1080P_RAW10_LINER"; //SENSOR_VGA_RAW10_LINER//
					skip_init = <1>;
				};
				sensor1 {
					subdev_name = "vivcam";
					idx = <3>; //<3>=vivcam3 : sc2310
					csi_idx = <1>; //<1>=CSI2X2_B
					mode_idx = <1>;
					path_type = "SENSOR_1920X1088_26FPS_RAW12_LINER";
					skip_init = <1>;
				};
			};
			dma {
				subdev_name = "vipre";
				idx = <0>;
				path_type = "VIPRE_CSI1_ISP0";
			};
		};

		video11: cam_dev@b00{
			compatible = "xuantie,th1520-video";
			status = "okay";
			channel0 {
				channel_id = <0>;
				status = "okay";
				sensor0 {
					subdev_name = "vivcam";
					idx = <4>; //sc132gs
					csi_idx = <2>; //<2>=CSI2X2_A
					flash_led_idx = <0>;
					mode_idx = <0>;
					path_type = "SENSOR_1080X1280_30FPS_RAW10_LINER";
				};
				dma {
					subdev_name = "vipre";
					idx = <0>;
					path_type = "VIPRE_CSI2_ISP0";
				};
				isp {
					subdev_name = "isp";
					idx = <0>;
					path_type = "ISP_MI_PATH_MP";
					output {
						max_width = <1920>;
						max_height = <1088>;
						bit_per_pixel = <12>;
						frame_count = <3>;
					};
				};
			};
		};

		video12: cam_dev@c00{ // TUNINGTOOL
			compatible = "xuantie,th1520-video";
			status = "okay";
			channel0 { // CSI2
				sensor0 {
					subdev_name = "vivcam";
					idx = <0>; //sc2310
					csi_idx = <0>; //<0>=CSI2
					mode_idx = <1>;
					path_type = "SENSOR_1920X1088_26FPS_RAW12_LINER";
					skip_init = <1>;
				};
				sensor1 {
					subdev_name = "vivcam";
					idx = <6>; //gc02m1b
					csi_idx = <0>; //<0>=CSI2
					mode_idx = <0>;
					path_type = "SENSOR_1600x1200_RAW10_LINER";
					skip_init = <1>;
				};
			};
			dma {
				subdev_name = "vipre";
				idx = <0>;
				path_type = "VIPRE_CSI0_ISP0";
			};
		};

		video15: cam_dev@f00{
			compatible = "xuantie,th1520-video";
			status = "okay";
			vi_mem_pool_region = <0>;
			channel0 {
				channel_id = <0>;
				status = "okay";
				sensor0 {
					subdev_name = "vivcam";
					idx = <0>; //<0>=vivcam0 :2310
					csi_idx = <0>; //<0>=CSI2
					flash_led_idx = <0>;
					mode_idx = <1>;
					path_type = "SENSOR_1920X1088_26FPS_RAW12_LINER";
				};
				sensor1 {
					subdev_name = "vivcam";
					idx = <7>; //imx334
					csi_idx = <0>; //<0>=CSI2
					mode_idx = <0>;
					path_type = "SENSOR_3840x2180_RAW12_LINER";
				};
				dma {
					subdev_name = "vipre";
					idx = <0>;
					path_type = "VIPRE_CSI0_DDR";
				};
			};
		};
	};
};

&gmac0 {
	pinctrl-names = "default";
	pinctrl-0 = <&gmac0_pins>;
	phy-handle = <&phy0>;
	phy-mode = "rgmii-id";
	status = "okay";
};

&gmac1 {
	pinctrl-names = "default";
	pinctrl-0 = <&gmac1_pins>;
	phy-handle = <&phy1>;
	phy-mode = "rgmii-id";
	status = "okay";
};

&i2c0 {
	pinctrl-names = "default";
	pinctrl-0 = <&i2c0_pins>;
	clock-frequency = <400000>;
	i2c-sda-hold-time-ns = <300>;
	i2c-sda-falling-time-ns = <510>;
	i2c-scl-falling-time-ns = <510>;
	status = "okay";

	eeprom@50 {
		compatible = "atmel,24c32";
		reg = <0x50>;
		pagesize = <32>;
	};

	touch@5d {
			#gpio-cells = <2>;
			reg = <0x5d>;
			interrupts = <8 IRQ_TYPE_LEVEL_LOW>;
			irq-gpios = <&gpio1 8 0>;
			reset-gpios = <&gpio1 7 0>;
			AVDD28-supply = <&reg_tp0_pwr>;
			status = "disbale";
	};
};

&i2c1 {
	pinctrl-names = "default";
	pinctrl-0 = <&i2c1_pins>;
	clock-frequency = <400000>;
	i2c-sda-hold-time-ns = <300>;
	i2c-sda-falling-time-ns = <510>;
	i2c-scl-falling-time-ns = <510>;
	status = "okay";

	touch1@5d {
		#gpio-cells = <2>;
		reg = <0x5d>;
		interrupts = <12 IRQ_TYPE_LEVEL_LOW>;
		irq-gpios = <&gpio1 12 0>;
		reset-gpios = <&gpio1 11 0>;
		AVDD28-supply = <&reg_tp1_pwr>;
		status = "disbale";
	};
};

&i2c2 {
	pinctrl-names = "default";
	pinctrl-0 = <&i2c2_pins>;
	clock-frequency = <400000>;
	i2c-sda-hold-time-ns = <300>;
	i2c-sda-falling-time-ns = <510>;
	i2c-scl-falling-time-ns = <510>;
	status = "okay";

	eeprom@50 {
		compatible = "atmel,24c32";
		reg = <0x50>;
		pagesize = <32>;
	};
};

&i2c3 {
	pinctrl-names = "default";
	pinctrl-0 = <&i2c3_pins>;
	clock-frequency = <400000>;
	i2c-sda-hold-time-ns = <300>;
	i2c-sda-falling-time-ns = <510>;
	i2c-scl-falling-time-ns = <510>;
	status = "okay";

	eeprom@50 {
		compatible = "atmel,24c32";
		reg = <0x50>;
		pagesize = <32>;
	};
};

&i2c4 {
	pinctrl-names = "default";
	pinctrl-0 = <&i2c4_pins>;
	clock-frequency = <400000>;
	i2c-sda-hold-time-ns = <300>;
	i2c-sda-falling-time-ns = <510>;
	i2c-scl-falling-time-ns = <510>;
	status = "okay";

	eeprom@50 {
		compatible = "atmel,24c32";
		reg = <0x50>;
		pagesize = <32>;
	};

	pcal6408ahk_a: gpio@20 {
		compatible = "nxp,pcal9554b";
		reg = <0x20>;
		gpio-controller;
		#gpio-cells = <2>;
		gpio-line-names = "",
				  "",
				  "";
	};
};

&audio_i2c0 {
	clock-frequency = <100000>;
	status = "okay";
	pinctrl-names = "default";
	pinctrl-0 = <&aud_i2c0_pa_pins>,
				<&aud_i2c0_pins>;
};

&audio_i2c1 {
	clock-frequency = <100000>;
	status = "okay";
	pinctrl-names = "default";
	pinctrl-0 = <&aud_i2c1_pa_pins>,
				<&aud_i2c1_pins>;

	pcal6408ahk_b: gpio@20 {
		compatible = "nxp,pcal9554b";
		reg = <0x20>;
		gpio-controller;
		#gpio-cells = <2>;
	};
};

&mdio0 {
	pinctrl-names = "default";
	pinctrl-0 = <&mdio0_pins>;

	phy0: ethernet-phy@1 {
		reg = <1>;
	};

	phy1: ethernet-phy@2 {
		reg = <2>;
	};
};

&padctrl0_apsys {
	gmac0_pins: gmac0-0 {
		tx-pins {
			pins = "GMAC0_TX_CLK",
			       "GMAC0_TXEN",
			       "GMAC0_TXD0",
			       "GMAC0_TXD1",
			       "GMAC0_TXD2",
			       "GMAC0_TXD3";
			function = "gmac0";
			bias-disable;
			drive-strength = <25>;
			input-disable;
			input-schmitt-disable;
			slew-rate = <0>;
		};

		rx-pins {
			pins = "GMAC0_RX_CLK",
			       "GMAC0_RXDV",
			       "GMAC0_RXD0",
			       "GMAC0_RXD1",
			       "GMAC0_RXD2",
			       "GMAC0_RXD3";
			function = "gmac0";
			bias-disable;
			drive-strength = <1>;
			input-enable;
			input-schmitt-disable;
			slew-rate = <0>;
		};
	};

	gmac1_pins: gmac1-0 {
		tx-pins {
			pins = "GPIO2_18", /* GMAC1_TX_CLK */
			       "GPIO2_20", /* GMAC1_TXEN */
			       "GPIO2_21", /* GMAC1_TXD0 */
			       "GPIO2_22", /* GMAC1_TXD1 */
			       "GPIO2_23", /* GMAC1_TXD2 */
			       "GPIO2_24"; /* GMAC1_TXD3 */
			function = "gmac1";
			bias-disable;
			drive-strength = <25>;
			input-disable;
			input-schmitt-disable;
			slew-rate = <0>;
		};

		rx-pins {
			pins = "GPIO2_19", /* GMAC1_RX_CLK */
			       "GPIO2_25", /* GMAC1_RXDV */
			       "GPIO2_30", /* GMAC1_RXD0 */
			       "GPIO2_31", /* GMAC1_RXD1 */
			       "GPIO3_0",  /* GMAC1_RXD2 */
			       "GPIO3_1";  /* GMAC1_RXD3 */
			function = "gmac1";
			bias-disable;
			drive-strength = <1>;
			input-enable;
			input-schmitt-disable;
			slew-rate = <0>;
		};
	};

	i2c2_pins: i2c2-0 {
		i2c-pins {
			pins = "I2C2_SCL", "I2C2_SDA";
			function = "i2c";
			bias-disable;
			drive-strength = <7>;
			input-enable;
			input-schmitt-enable;
			slew-rate = <0>;
		};
	};

	i2c3_pins: i2c3-0 {
		i2c-pins {
			pins = "I2C3_SCL", "I2C3_SDA";
			function = "i2c";
			bias-disable;
			drive-strength = <7>;
			input-enable;
			input-schmitt-enable;
			slew-rate = <0>;
		};
	};

	mdio0_pins: mdio0-0 {
		mdc-pins {
			pins = "GMAC0_MDC";
			function = "gmac0";
			bias-disable;
			drive-strength = <13>;
			input-disable;
			input-schmitt-disable;
			slew-rate = <0>;
		};

		mdio-pins {
			pins = "GMAC0_MDIO";
			function = "gmac0";
			bias-disable;
			drive-strength = <13>;
			input-enable;
			input-schmitt-enable;
			slew-rate = <0>;
		};
	};

	uart0_pins: uart0-0 {
		tx-pins {
			pins = "UART0_TXD";
			function = "uart";
			bias-disable;
			drive-strength = <3>;
			input-disable;
			input-schmitt-disable;
			slew-rate = <0>;
		};

		rx-pins {
			pins = "UART0_RXD";
			function = "uart";
			bias-disable;
			drive-strength = <1>;
			input-enable;
			input-schmitt-enable;
			slew-rate = <0>;
		};
	};

	spi_pins: spi-0 {
		spi-pins {
			pins = "SPI_SCLK", "SPI_MOSI", "SPI_MISO";
			function = "spi";
			bias-disable;
			drive-strength = <7>;
			input-enable;
			input-schmitt-enable;
			slew-rate = <0>;
		};
	};

	qspi0_pins: qspi0-0 {
		qspi-pins {
			pins = "QSPI0_SCLK", "QSPI0_D0_MOSI", "QSPI0_D1_MISO", "QSPI0_D2_WP", "QSPI0_D3_HOLD";
			function = "qspi";
			bias-disable;
			drive-strength = <7>;
			input-enable;
			input-schmitt-enable;
			slew-rate = <0>;
		};
	};

	sdio0_pins: sdio0-0 {
		detn-pins {
			pins = "SDIO0_DETN";
			function = "sdio";
			bias-disable; /* external pull-up */
			drive-strength = <1>;
			input-enable;
			input-schmitt-enable;
			slew-rate = <0>;
		};
	};

	sdio0_pins: sdio0-0 {
		detn-pins {
			pins = "SDIO0_DETN";
			function = "sdio";
			bias-disable; /* external pull-up */
			drive-strength = <1>;
			input-enable;
			input-schmitt-enable;
			slew-rate = <0>;
		};
	};

	pwm0_pins: pwm0-0 {
		pwm-pins {
			pins = "GPIO3_2";
			function = "pwm";
			bias-disable;
			drive-strength = <13>;
			input-enable;
			input-schmitt-disable;
			slew-rate = <0>;
		};
	};

	pwm1_pins: pwm1-0 {
		pwm-pins {
			pins = "GPIO3_3";
			function = "pwm";
			bias-disable;
			drive-strength = <13>;
			input-enable;
			input-schmitt-disable;
			slew-rate = <0>;
		};
	};
};

&padctrl1_apsys {
	i2c0_pins: i2c0-0 {
		i2c-pins {
			pins = "I2C0_SCL", "I2C0_SDA";
			function = "i2c";
			bias-disable;
			drive-strength = <7>;
			input-enable;
			input-schmitt-enable;
			slew-rate = <0>;
		};
	};

	i2c1_pins: i2c1-0 {
		i2c-pins {
			pins = "I2C1_SCL", "I2C1_SDA";
			function = "i2c";
			bias-disable;
			drive-strength = <7>;
			input-enable;
			input-schmitt-enable;
			slew-rate = <0>;
		};
	};

	i2c4_pins: i2c4-0 {
		i2c-pins {
			pins = "GPIO0_22", "GPIO0_23";
			function = "i2c";
			bias-disable;
			drive-strength = <7>;
			input-enable;
			input-schmitt-enable;
			slew-rate = <0>;
		};
	};

	qspi1_pins: qspi1-0 {
		qspi-pins {
			pins = "QSPI1_SCLK", "QSPI1_D0_MOSI", "QSPI1_D1_MISO", "QSPI1_D2_WP", "QSPI1_D3_HOLD";
			function = "qspi";
			bias-disable;
			drive-strength = <7>;
			input-enable;
			input-schmitt-enable;
			slew-rate = <0>;
		};
	};

	uart1_pins: uart1-0 {
		tx-pins {
			pins = "UART1_TXD";
			function = "uart";
			bias-disable;
			drive-strength = <3>;
			input-disable;
			input-schmitt-disable;
			slew-rate = <0>;
		};

		rx-pins {
			pins = "UART1_RXD";
			function = "uart";
			bias-disable;
			drive-strength = <1>;
			input-enable;
			input-schmitt-enable;
			slew-rate = <0>;
		};
	};

	uart3_pins: uart3-0 {
		tx-pins {
			pins = "UART3_TXD";
			function = "uart";
			bias-disable;
			drive-strength = <3>;
			input-disable;
			input-schmitt-disable;
			slew-rate = <0>;
		};

		rx-pins {
			pins = "UART3_RXD";
			function = "uart";
			bias-disable;
			drive-strength = <1>;
			input-enable;
			input-schmitt-enable;
			slew-rate = <0>;
		};
	};

	uart4_pins: uart4-0 {
		tx-pins {
			pins = "UART4_TXD";
			function = "uart";
			bias-disable;
			drive-strength = <3>;
			input-disable;
			input-schmitt-disable;
			slew-rate = <0>;
		};

		rx-pins {
			pins = "UART4_RXD";
			function = "uart";
			bias-disable;
			drive-strength = <1>;
			input-enable;
			input-schmitt-enable;
			slew-rate = <0>;
		};
	};

	pinctrl_wifi_wake: wifi_grp {
		wifi-pins {
			pins = "GPIO0_27";
			function = "gpio";
			bias-disable;
			drive-strength = <7>;
			input-disable;
			input-schmitt-disable;
			slew-rate = <0>;
		};
	};

	pinctrl_bt_wake: bt_grp {
		bt-pins {
			pins = "GPIO0_28";
			function = "gpio";
			bias-disable;
			drive-strength = <7>;
			input-disable;
			input-schmitt-disable;
			slew-rate = <0>;
		};
	};

	iso7816_pins: iso7816-0 {
		det-pin {
			pins = "QSPI1_SCLK";
			function = "iso7816";
			bias-disable;
			drive-strength = <7>;
			input-enable;
			input-schmitt-enable;
			slew-rate = <0>;
		};

		iso7816-pins {
			pins = "QSPI1_D0_MOSI", "QSPI1_D1_MISO", "QSPI1_D2_WP", "QSPI1_D3_HOLD";
			function = "iso7816";
			bias-pull-up;
			drive-strength = <7>;
			input-enable;
			input-schmitt-enable;
			slew-rate = <0>;
		};
	};
};

&padctrl_aosys {
	aud_i2c0_pa_pins: aud-i2c0-pa-0 {
		i2c-pa-pins {
			pins = "AUDIO_PA6", "AUDIO_PA7";
			function = "audio";
			bias-disable;
			drive-strength = <0>;
			slew-rate = <0>;
		};
	};
	aud_i2c1_pa_pins: aud-i2c1-pa-0 {
		i2c-pa-pins {
			pins = "AUDIO_PA13", "AUDIO_PA16";
			function = "audio";
			bias-disable;
			drive-strength = <0>;
			slew-rate = <0>;
		};
	};
	i2s0_pa_pins: i2s0-pa-0 {
		i2s-pa-pins {
			pins = "AUDIO_PA9", "AUDIO_PA10", "AUDIO_PA11", "AUDIO_PA12";
			function = "audio";
			bias-disable;
			drive-strength = <0>;
			slew-rate = <0>;
		};
	};
	i2s1_pa_pins: i2s1-pa-0 {
		i2s-pa-pins {
			pins = "AUDIO_PA14", "AUDIO_PA15", "AUDIO_PA17";
			function = "audio";
			bias-disable;
			drive-strength = <0>;
			slew-rate = <0>;
		};
	};
	i2s_8ch_bus_pa_pins: i2s-8ch-bus-pa-0 {
		i2s-pa-pins {
			pins = "AUDIO_PA2", "AUDIO_PA3", "AUDIO_PA8";
			function = "audio";
			bias-disable;
			drive-strength = <0>;
			slew-rate = <0>;
		};
	};
	i2s_8ch_sd0_pa_pins: i2s-8ch-sd0-pa-0 {
		i2s-pa-pins {
			pins = "AUDIO_PA4";
			function = "audio";
			bias-disable;
			drive-strength = <0>;
			slew-rate = <0>;
		};
	};
	i2s_8ch_sd1_pa_pins: i2s-8ch-sd1-pa-0 {
		i2s-pa-pins {
			pins = "AUDIO_PA5";
			function = "audio";
			bias-disable;
			drive-strength = <0>;
			slew-rate = <0>;
		};
	};
	i2s_8ch_sd2_pa_pins: i2s-8ch-sd2-pa-0 {
		i2s-pa-pins {
			pins = "AUDIO_PA0";
			function = "audio";
			bias-disable;
			drive-strength = <0>;
			slew-rate = <0>;
		};
	};
	i2s_8ch_sd3_pa_pins: i2s-8ch-sd3-pa-0 {
		i2s-pa-pins {
			pins = "AUDIO_PA1";
			function = "audio";
			bias-disable;
			drive-strength = <0>;
			slew-rate = <0>;
		};
	};
};

&padctrl_audiosys {
	aud_i2c0_pins: aud-i2c0-0 {
		i2c-pins {
			pins = "PA6_FUNC", "PA7_FUNC";
			function = "aud_i2c0";
			bias-disable;
			drive-strength = <7>;
			input-schmitt-disable;
			slew-rate = <0>;
		};
	};
	aud_i2c1_pins: aud-i2c1-0 {
		i2c-pins {
			pins = "PA13_FUNC", "PA16_FUNC";
			function = "aud_i2c1";
			bias-disable;
			drive-strength = <7>;
			input-schmitt-disable;
			slew-rate = <0>;
		};
	};
	i2s0_pins: i2s0-0 {
		i2s-pins {
			pins = "PA9_FUNC", "PA10_FUNC", "PA11_FUNC", "PA12_FUNC";
			function = "aud_i2s0";
			bias-disable;
			drive-strength = <13>;
			input-schmitt-disable;
			slew-rate = <0>;
		};
	};
	i2s1_pins: i2s1-0 {
		i2s-pins {
			pins = "PA14_FUNC", "PA15_FUNC", "PA17_FUNC";
			function = "aud_i2s1";
			bias-disable;
			drive-strength = <13>;
			input-schmitt-disable;
			slew-rate = <0>;
		};
	};
	i2s_8ch_bus_pins: i2s-8ch-bus-0 {
		i2s-pins {
			pins = "PA2_FUNC", "PA3_FUNC", "PA8_FUNC";
			function = "aud_i2s_8ch";
			bias-disable;
			drive-strength = <13>;
			input-schmitt-disable;
			slew-rate = <0>;
		};
	};
	i2s_8ch_sd0_pins: i2s-8ch-sd0-0 {
		i2s-pins {
			pins = "PA4_FUNC";
			function = "aud_i2s_8ch";
			bias-disable;
			drive-strength = <13>;
			input-schmitt-disable;
			slew-rate = <0>;
		};
	};
	i2s_8ch_sd1_pins: i2s-8ch-sd1-0 {
		i2s-pins {
			pins = "PA5_FUNC";
			function = "aud_i2s_8ch";
			bias-disable;
			drive-strength = <13>;
			input-schmitt-disable;
			slew-rate = <0>;
		};
	};
	i2s_8ch_sd2_pins: i2s-8ch-sd2-0 {
		i2s-pins {
			pins = "PA0_FUNC";
			function = "aud_i2s_8ch";
			bias-disable;
			drive-strength = <13>;
			input-schmitt-disable;
			slew-rate = <0>;
		};
	};
	i2s_8ch_sd3_pins: i2s-8ch-sd3-0 {
		i2s-pins {
			pins = "PA1_FUNC";
			function = "aud_i2s_8ch";
			bias-disable;
			drive-strength = <13>;
			input-schmitt-disable;
			slew-rate = <0>;
		};
	};
	tdm_pins: tdm-0 {
		clk-pins {
			pins = "PA27_FUNC", "PA28_FUNC";
			function = "aud_tdm";
			bias-disable;
			drive-strength = <12>;
			input-schmitt-disable;
			slew-rate = <0>;
		};
		data-pins {
			pins = "PA29_FUNC";
			function = "aud_tdm";
			bias-disable;
			drive-strength = <0>;
			input-schmitt-disable;
			slew-rate = <0>;
		};
	};
	spdif0_pins: spdif0-0 {
		rx-pins {
			pins = "PA21_FUNC";
			function = "aud_spdif";
			bias-disable;
			drive-strength = <12>;
			input-schmitt-disable;
			slew-rate = <0>;
		};
		tx-pins {
			pins = "PA22_FUNC";
			function = "aud_spdif";
			bias-disable;
			drive-strength = <0>;
			input-schmitt-disable;
			slew-rate = <0>;
		};
	};
	spdif1_pins: spdif1-0 {
		tx-pins {
			pins = "PA23_FUNC";
			function = "aud_spdif";
			bias-disable;
			drive-strength = <12>;
			input-schmitt-disable;
			slew-rate = <0>;
		};
		rx-pins {
			pins = "PA24_FUNC";
			function = "aud_spdif";
			bias-disable;
			drive-strength = <0>;
			input-schmitt-disable;
			slew-rate = <0>;
		};
	};
};

&uart0 {
	pinctrl-names = "default";
	pinctrl-0 = <&uart0_pins>;
	status = "okay";
};

&uart1 {
	pinctrl-names = "default";
	pinctrl-0 = <&uart1_pins>;
};

&uart3 {
	pinctrl-names = "default";
	pinctrl-0 = <&uart3_pins>;
};

&uart4 {
	pinctrl-names = "default";
	pinctrl-0 = <&uart4_pins>;
	status = "okay";
};

&usb {
	status = "okay";
};

&usb_dwc3 {
	status = "okay";
	#address-cells = <1>;
	#size-cells = <0>;
};

&adc {
	vref-supply = <&reg_vref_1v8>;
	#io-channel-cells = <1>;
	status = "okay";
};

&spi {
	num-cs = <1>;
	cs-gpios = <&gpio2 15 0>;
	rx-sample-delay-ns = <10>;
	pinctrl-names = "default";
	pinctrl-0 = <&spi_pins>;
	status = "okay";

	spi_norflash@0 {
		status = "okay";
		#address-cells = <1>;
		#size-cells = <1>;
		compatible = "winbond,w25q64jwm", "jedec,spi-nor";
		reg = <0>;
		spi-max-frequency = <50000000>;
		w25q,fast-read;
	};

	spidev@1 {
		status = "disable";
		compatible = "spidev";
		#address-cells = <0x1>;
		#size-cells = <0x1>;
		reg = <0x1>;
		spi-max-frequency = <50000000>;
	};

	tpm_tis@0 {
		status = "disable";
 		compatible = "tcg,tpm_tis-spi";
		reg = <0>;
 		spi-max-frequency = <10000000>;
	};
};

&qspi0 {
	num-cs = <1>;
	cs-gpios = <&gpio2 3 0>;
	pinctrl-names = "default";
	pinctrl-0 = <&qspi0_pins>;
	status = "okay";

	spi-flash@0 {
		#address-cells = <1>;
		#size-cells = <1>;
		compatible = "spi-nand";
		spi-max-frequency = <100000000>;
		spi-tx-bus-width = <4>;
		spi-rx-bus-width = <4>;
		reg = <0>;

		partition@0 {
			label = "ubi1";
			reg = <0x00000000 0x08000000>;
		};
	};
};

&qspi1 {
	num-cs = <1>;
	cs-gpios = <&gpio0 1 0>;
	pinctrl-names = "default";
	pinctrl-0 = <&qspi1_pins>;
	status = "okay";

	spi-flash@0 {
		#address-cells = <1>;
		#size-cells = <1>;
		compatible = "spi-nand";
		spi-max-frequency = <66000000>;
		spi-tx-bus-width = <4>;
		spi-rx-bus-width = <4>;
		reg = <0>;

		partition@0 {
			label = "ubi2";
			reg = <0x00000000 0x08000000>;
		};
	};
};

&sdio1 {
	max-frequency = <100000000>;
	bus-width = <4>;
	pull_up;
	no-sd;
	no-mmc;
	non-removable;
	io_fixed_1v8;
	post-power-on-delay-ms = <50>;
	wprtn_ignore;
	cap-sd-highspeed;
	wakeup-source;
	keep-power-in-suspend;
	status = "okay";
};

&aon {
    log-memory-region = <&aon_log_mem>;
	status = "okay";
};

&resmem {
	#address-cells = <2>;
	#size-cells = <2>;
	ranges;

	/* global autoconfigured region for contiguous allocations */
	cmamem: linux,cma {
		compatible = "shared-dma-pool";
		reusable;
		size = <0 0x14000000>; // 512MB on lpi4a (SOM)
		alloc-ranges = <00 0xe4000000 0 0x14000000>;
		linux,cma-default;
	};
	dsp0_mem: memory@20000000 {             /**0x2000_0000~0x2040_0000 4M**/
		reg = <0x0 0x20000000 0x0 0x00280000   /* DSP FW code&data section 2.5M*/
			0x0 0x20280000 0x0 0x00001000   /* DSP communication area 4K*/
			0x0 0x20281000 0x0 0x00007000  /* Panic/log page 28K */
			0x0 0x20288000 0x0 0x00178000>;  /* DSP shared memory 1.5M-32K*/
		};
	dsp1_mem: memory@20400000 {             /**0x2040_0000~0x2080_0000 4M**/
		reg = <0x0 0x20400000 0x0 0x00280000  /* DSP FW code&data section */
			0x0 0x20680000 0x0 0x00001000 /* DSP communication area */
			0x0 0x20681000 0x0 0x00007000    /* Panic/log page*/
			0x0 0x20688000 0x0 0x00178000>;  /* DSP shared memory */
		};
    vi_mem: framebuffer@0f800000 {
		reg = <0x0 0x0F800000 0x0 0x05400000	/* vi_mem_pool_region[0]  84 MB (default) */
		       0x0 0x14C00000 0x0 0x01D00000	/* vi_mem_pool_region[1]  29 MB */
		       0x0 0x16900000 0x0 0x03200000>;	/* vi_mem_pool_region[2]  50 MB */
	};

    audio_text_mem: memory@32000000 {
		reg = <0x0 0x32000000 0x0 0xE00000>;
		//no-map;
    };
    audio_data_mem: memory@32E00000 {
		reg = <0x0 0x32E00000 0x0 0x600000>;
		//no-map;
    };
	audio_log_mem: memory@33400000 {
        reg = <0x0 0x33400000 0x0 0x200000>;
	};
	//Note: with "no-map" reserv mem not saved in hibernation
	rpmsgmem: memory@1E000000 {
		reg = <0x0 0x1E000000 0x0 0x10000>;
	};
	aon_log_mem: memory@33600000 {
        reg = <0x0 0x33600000 0x0 0x200000>;
	};
	regdump_mem: memory@38400000 {
		reg = <0x0 0x38400000 0x0 0x1400000>;
		no-map;
	};
};

&regdump {
	memory-region = <&regdump_mem>;
	status = "okay";
};

&ap_i2s {
	status = "okay";
};

&cpus {
	c910_0: cpu@0 {
		dvdd-supply = <&dvdd_cpu_reg>;
		dvddm-supply = <&dvddm_cpu_reg>;

		operating-points = <
			/* kHz    uV */
			300000  600000
			400000  700000
			500000  700000
			600000  700000
			702000  700000
			800000  700000
			900000  800000
			1000000 800000
			1104000 800000
			1200000 800000
			1296000 800000
			1404000 800000
			1500000 800000
			1608000 1000000
			1704000 1000000
			1848000 1000000
		>;
		th1520,dvddm-operating-points = <
			/* kHz   uV */
			300000  800000
			400000  800000
			500000  800000
			600000  800000
			702000  800000
			800000  800000
			900000  800000
			1000000 800000
			1104000 800000
			1200000 800000
			1296000 800000
			1404000 800000
			1500000 800000
			1608000 1000000
			1704000 1000000
			1848000 1000000
		>;
	};
	c910_1: cpu@1 {
		dvdd-supply = <&dvdd_cpu_reg>;
		dvddm-supply = <&dvddm_cpu_reg>;

		operating-points = <
			/* kHz    uV */
			300000  600000
			400000  700000
			500000  700000
			600000  700000
			702000  700000
			800000  700000
			900000  800000
			1000000 800000
			1104000 800000
			1200000 800000
			1296000 800000
			1404000 800000
			1500000 800000
			1608000 1000000
			1704000 1000000
			1848000 1000000
		>;
		th1520,dvddm-operating-points = <
			/* kHz   uV */
			300000  800000
			400000  800000
			500000  800000
			600000  800000
			702000  800000
			800000  800000
			900000  800000
			1000000 800000
			1104000 800000
			1200000 800000
			1296000 800000
			1404000 800000
			1500000 800000
			1608000 1000000
			1704000 1000000
			1848000 1000000
		>;
	};
	c910_2: cpu@2 {
		dvdd-supply = <&dvdd_cpu_reg>;
		dvddm-supply = <&dvddm_cpu_reg>;

		operating-points = <
			/* kHz    uV */
			300000  600000
			400000  700000
			500000  700000
			600000  700000
			702000  700000
			800000  700000
			900000  800000
			1000000 800000
			1104000 800000
			1200000 800000
			1296000 800000
			1404000 800000
			1500000 800000
			1608000 1000000
			1704000 1000000
			1848000 1000000
		>;
		th1520,dvddm-operating-points = <
			/* kHz   uV */
			300000  800000
			400000  800000
			500000  800000
			600000  800000
			702000  800000
			800000  800000
			900000  800000
			1000000 800000
			1104000 800000
			1200000 800000
			1296000 800000
			1404000 800000
			1500000 800000
			1608000 1000000
			1704000 1000000
			1848000 1000000
		>;
	};
	c910_3: cpu@3 {
		dvdd-supply = <&dvdd_cpu_reg>;
		dvddm-supply = <&dvddm_cpu_reg>;

		operating-points = <
			/* kHz    uV */
			300000  600000
			400000  700000
			500000  700000
			600000  700000
			702000  700000
			800000  700000
			900000  800000
			1000000 800000
			1104000 800000
			1200000 800000
			1296000 800000
			1404000 800000
			1500000 800000
			1608000 1000000
			1704000 1000000
			1848000 1000000
		>;
		th1520,dvddm-operating-points = <
			/* kHz   uV */
			300000  800000
			400000  800000
			500000  800000
			600000  800000
			702000  800000
			800000  800000
			900000  800000
			1000000 800000
			1104000 800000
			1200000 800000
			1296000 800000
			1404000 800000
			1500000 800000
			1608000 1000000
			1704000 1000000
			1848000 1000000
		>;
	};
};

&osc {
	clock-frequency = <24000000>;
};

&osc_32k {
	clock-frequency = <32768>;
};

&rc_24m {
	clock-frequency = <24000000>;
};

&aonsys_clk {
	clock-frequency = <73728000>;
};

&audiosys_clk {
	clock-frequency = <294912000>;
};

&apb_clk {
	clock-frequency = <62500000>;
};

&sdhci_clk {
	clock-frequency = <198000000>;
};

&uart_sclk {
	clock-frequency = <100000000>;
};

&aogpio {
	gpio-line-names = "", "", "",
			  "GPIO00",
			  "GPIO04";
};

&gmac_clk {
	clock-frequency = <500000000>;
};

&gmac_axi_clk {
	clock-frequency = <100000000>;
};

&aon {
	dvdd_cpu_reg: appcpu_dvdd {
		compatible = "thead,th1520-aon-pmic";
		regulator-name = "appcpu_dvdd";
		regulator-min-microvolt = <300000>;
		regulator-max-microvolt = <1570000>;
		regulator-type = "dvdd";
		regulator-boot-on;
		regulator-always-on;
	};

	dvddm_cpu_reg: appcpu_dvddm {
		compatible = "thead,th1520-aon-pmic";
		regulator-name = "appcpu_dvddm";
		regulator-min-microvolt = <300000>;
		regulator-max-microvolt = <1570000>;
		regulator-type = "dvddm";
		regulator-dual-rail;
		regulator-boot-on;
		regulator-always-on;
	};

	soc_dvdd18_aon_reg: soc_dvdd18_aon {
		compatible = "thead,th1520-aon-pmic";
		regulator-name = "soc_dvdd18_aon";
		regulator-type = "common";
		regulator-boot-on;
		regulator-always-on;
	};

	soc_avdd33_usb3_reg: soc_avdd33_usb3 {
		compatible = "thead,th1520-aon-pmic";
		regulator-name = "soc_avdd33_usb3";
		regulator-type = "common";
		regulator-boot-on;
		regulator-always-on;
	};

	soc_dvdd08_aon_reg: soc_dvdd08_aon {
		compatible = "thead,th1520-aon-pmic";
		regulator-name = "soc_dvdd08_aon";
		regulator-type = "common";
		regulator-boot-on;
		regulator-always-on;
	};

	soc_dvdd08_ddr_reg: soc_dvdd08_ddr {
		compatible = "thead,th1520-aon-pmic";
		regulator-name = "soc_dvdd08_ddr";
		regulator-type = "common";
		regulator-boot-on;
		regulator-always-on;
	};

	soc_vdd_ddr_1v8_reg: soc_vdd_ddr_1v8 {
		compatible = "thead,th1520-aon-pmic";
		regulator-name = "soc_vdd_ddr_1v8";
		regulator-type = "common";
		regulator-boot-on;
		regulator-always-on;
	};

	soc_vdd_ddr_1v1_reg: soc_vdd_ddr_1v1 {
		compatible = "thead,th1520-aon-pmic";
		regulator-name = "soc_vdd_ddr_1v1";
		regulator-type = "common";
		regulator-boot-on;
		regulator-always-on;
	};

	soc_vdd_ddr_0v6_reg: soc_vdd_ddr_0v6 {
		compatible = "thead,th1520-aon-pmic";
		regulator-name = "soc_vdd_ddr_0v6";
		regulator-type = "common";
		regulator-boot-on;
		regulator-always-on;
	};

	soc_dvdd18_ap_reg: soc_dvdd18_ap {
		compatible = "thead,th1520-aon-pmic";
		regulator-name = "soc_dvdd18_ap";
		regulator-type = "common";
		regulator-boot-on;
		regulator-always-on;
	};

	soc_dvdd08_ap_reg: soc_dvdd08_ap {
		compatible = "thead,th1520-aon-pmic";
		regulator-name = "soc_dvdd08_ap";
		regulator-type = "common";
		regulator-boot-on;
		regulator-always-on;
	};

	soc_avdd08_mipi_hdmi_reg: soc_avdd08_mipi_hdmi {
		compatible = "thead,th1520-aon-pmic";
		regulator-name = "soc_avdd08_mipi_hdmi";
		regulator-type = "common";
		regulator-boot-on;
		regulator-always-on;
	};

	soc_avdd18_mipi_hdmi_reg: soc_avdd18_mipi_hdmi {
		compatible = "thead,th1520-aon-pmic";
		regulator-name = "soc_avdd18_mipi_hdmi";
		regulator-type = "common";
		regulator-boot-on;
		regulator-always-on;
	};

	soc_vdd33_emmc_reg: soc_vdd33_emmc {
		compatible = "thead,th1520-aon-pmic";
		regulator-name = "soc_dvdd33_emmc";
		regulator-type = "common";
		regulator-boot-on;
		regulator-always-on;
	};

	soc_vdd18_emmc_reg: soc_vdd18_emmc {
		compatible = "thead,th1520-aon-pmic";
		regulator-name = "soc_dvdd18_emmc";
		regulator-type = "common";
		regulator-boot-on;
		regulator-always-on;
	};

	soc_dovdd18_scan_reg: soc_dovdd18_scan {
		compatible = "thead,th1520-aon-pmic";
		regulator-name = "soc_dovdd18_scan";
		regulator-type = "common";
		regulator-min-microvolt = <900000>;
		regulator-max-microvolt = <3600000>;
	};

	soc_dvdd12_scan_reg: soc_dvdd12_scan {
		compatible = "thead,th1520-aon-pmic";
		regulator-name = "soc_dvdd12_scan";
		regulator-type = "common";
		regulator-min-microvolt = <900000>;
		regulator-max-microvolt = <3600000>;
	};

	soc_avdd28_scan_en_reg: soc_avdd28_scan_en {
		compatible = "thead,th1520-aon-pmic";
		regulator-name = "soc_avdd28_scan_en";
		regulator-type = "gpio";
	};

    	soc_vext_2v8_reg: soc_vext_2v8 {
	    	compatible = "thead,th1520-aon-pmic";
	    	regulator-name = "soc_vext_2v8";
	    	regulator-type = "common";
	    	regulator-boot-on;
		regulator-always-on;
	};

	soc_avdd28_rgb_reg: soc_avdd28_rgb {
		compatible = "thead,th1520-aon-pmic";
		regulator-name = "soc_avdd28_rgb";
		regulator-type = "common";
		regulator-min-microvolt = <2200000>;
		regulator-max-microvolt = <3475000>;
		regulator-boot-on;
		regulator-always-on;
	};

	soc_dovdd18_rgb_reg: soc_dovdd18_rgb {
		compatible = "thead,th1520-aon-pmic";
		regulator-name = "soc_dovdd18_rgb";
		regulator-type = "common";
		regulator-min-microvolt = <1200000>;
		regulator-max-microvolt = <3600000>;
		regulator-boot-on;
		regulator-always-on;
	};

	soc_dvdd12_rgb_reg: soc_dvdd12_rgb {
		compatible = "thead,th1520-aon-pmic";
		regulator-name = "soc_dvdd12_rgb";
		regulator-type = "common";
		regulator-min-microvolt = <400000>;
		regulator-max-microvolt = <1675000>;
		regulator-boot-on;
		regulator-always-on;
	};

	soc_avdd25_ir_reg: soc_avdd25_ir {
		compatible = "thead,th1520-aon-pmic";
		regulator-name = "soc_avdd25_ir";
		regulator-type = "common";
		regulator-min-microvolt = <2200000>;
		regulator-max-microvolt = <3475000>;
		regulator-boot-on;
		regulator-always-on;
	};

	soc_dovdd18_ir_reg: soc_dovdd18_ir {
		compatible = "thead,th1520-aon-pmic";
		regulator-name = "soc_dovdd18_ir";
		regulator-type = "common";
		regulator-min-microvolt = <1200000>;
		regulator-max-microvolt = <3600000>;
		regulator-boot-on;
		regulator-always-on;
	};

	soc_dvdd12_ir_reg: soc_dvdd12_ir {
		compatible = "thead,th1520-aon-pmic";
		regulator-name = "soc_dvdd12_ir";
		regulator-type = "common";
		regulator-min-microvolt = <400000>;
		regulator-max-microvolt = <1675000>;
		regulator-boot-on;
		regulator-always-on;
	};

};

&dmac0 {
	status = "okay";
};

&dmac2 {
	status = "okay";
};

&emmc {
       bus-width = <8>;
       max-frequency = <198000000>;
       mmc-hs400-1_8v;
       non-removable;
       no-sdio;
       no-sd;
       wprtn_ignore;
       status = "okay";
};

&sdio0 {
       pinctrl-names = "default";
       pinctrl-0 = <&sdio0_pins>;
       bus-width = <4>;
       max-frequency = <198000000>;
       status = "okay";
};

&gpio0 {
	gpio-line-names = "", "", "", "", "", "", "", "", "", "",
			  "", "", "", "", "", "", "", "", "", "",
			  "", "", "", "",
			  "GPIO07",
			  "GPIO08",
			  "",
			  "GPIO01",
			  "GPIO02";
};

&gpio1 {
	gpio-line-names = "", "", "",
			  "GPIO11",
			  "GPIO12",
			  "GPIO13",
			  "GPIO14",
			  "", "", "", "", "", "", "", "", "", "",
			  "", "", "", "", "",
			  "GPIO06";
};

&gpio2 {
	gpio-line-names = "GPIO03",
			  "GPIO05";
};

&gpio3 {
	gpio-line-names = "", "",
			  "GPIO09",
			  "GPIO10";
};

&gpu {
	status = "okay";
};

&npu {
	vha_clk_rate = <1000000000>;
	status = "okay";
};

&npu_opp_table {
	opp-1000000000 {
		opp-suspend;
	};
};

&eip_28 {
	status = "okay";
};

&isp0 {
	status = "okay";
};

&isp1 {
	status = "okay";
};

&isp_ry0 {
	status = "okay";
};

&dewarp {
	status = "okay";
};

&dec400_isp0 {
	status = "okay";
};

&dec400_isp1 {
	status = "okay";
};

&dec400_isp2 {
	status = "okay";
};

&bm_visys {
	status = "okay";
};

&bm_csi0 {
	status = "okay";
};

&bm_csi1 {
	status = "okay";
};

&bm_csi2 {
	status = "okay";
};

&vidmem {
	status = "okay";
	memory-region = <&vi_mem>;
};

&vi_pre {
	status = "okay";
};
&xtensa_dsp {
	status = "okay";
};

&xtensa_dsp0 {
	status = "okay";
	memory-region = <&dsp0_mem>;
};

&xtensa_dsp1 {
	status = "okay";
	memory-region = <&dsp1_mem>;
};

